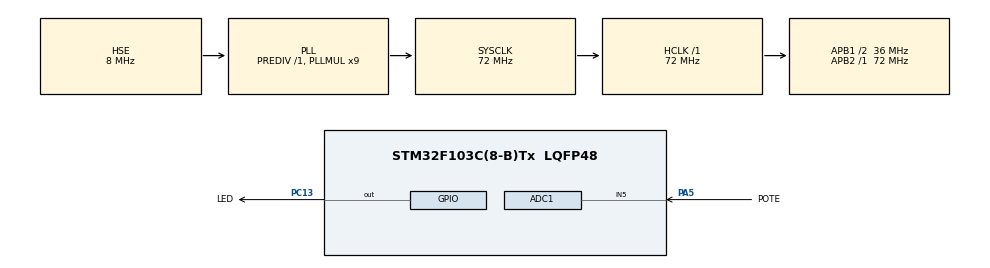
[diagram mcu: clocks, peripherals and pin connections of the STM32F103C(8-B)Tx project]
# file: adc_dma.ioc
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Mcu.Family=STM32F1
RCC.PLLSourceVirtual=RCC_PLLSOURCE_HSE
Dma.ADC1.0.Instance=DMA1_Channel1
ADC1.Rank-0\#ChannelRegularConversion=1
PD1-OSC_OUT.Mode=HSE-External-Oscillator
ADC1.ContinuousConvMode=ENABLE
PC13-TAMPER-RTC.Signal=GPIO_Output
NVIC.TIM1_UP_IRQn=true\:0\:0\:false\:false\:true\:false\:true
PD0-OSC_IN.Signal=RCC_OSC_IN
RCC.APB1CLKDivider=RCC_HCLK_DIV2
RCC.SYSCLKSource=RCC_SYSCLKSOURCE_PLLCLK
ProjectManager.StackSize=0x400
PD1-OSC_OUT.Signal=RCC_OSC_OUT
RCC.ADCPresc=RCC_ADCPCLK2_DIV6
PA13.Signal=SYS_JTMS-SWDIO
Dma.ADC1.0.PeriphDataAlignment=DMA_PDATAALIGN_HALFWORD
ProjectManager.TargetToolchain=STM32CubeIDE
Dma.ADC1.0.Mode=DMA_CIRCULAR
RCC.HCLKFreq_Value=72000000
Dma.ADC1.0.Priority=DMA_PRIORITY_LOW
RCC.APB2TimFreq_Value=72000000
Dma.ADC1.0.Direction=DMA_PERIPH_TO_MEMORY
RCC.USBFreq_Value=72000000
Dma.ADC1.0.MemDataAlignment=DMA_MDATAALIGN_WORD
RCC.AHBFreq_Value=72000000
PD0-OSC_IN.Mode=HSE-External-Oscillator
PA5.Signal=ADCx_IN5
ADC1.Channel-0\#ChannelRegularConversion=ADC_CHANNEL_5
board=custom
PC13-TAMPER-RTC.GPIO_Label=LED
RCC.PLLMUL=RCC_PLL_MUL9
RCC.APB2Freq_Value=72000000
PA14.Mode=Serial_Wire
VP_SYS_VS_tim1.Mode=TIM1
Dma.ADC1.0.PeriphInc=DMA_PINC_DISABLE
PA13.Mode=Serial_Wire
Mcu.Name=STM32F103C(8-B)Tx
ADC1.SamplingTime-0\#ChannelRegularConversion=ADC_SAMPLETIME_1CYCLE_5
RCC.SYSCLKFreq_VALUE=72000000
Mcu.Package=LQFP48
ADC1.master=1
NVIC.TimeBase=TIM1_UP_IRQn
PA5.GPIO_Label=POTE
NVIC.TimeBaseIP=TIM1
PA14.Signal=SYS_JTCK-SWCLK
Dma.ADC1.0.MemInc=DMA_MINC_ENABLE
ProjectManager.HeapSize=0x200
SH.ADCx_IN5.0=ADC1_IN5,IN5
NVIC.PriorityGroup=NVIC_PRIORITYGROUP_4
ADC1.NbrOfConversionFlag=1
RCC.APB1TimFreq_Value=72000000
NVIC.DMA1_Channel1_IRQn=true\:5\:0\:true\:false\:true\:true\:true
Dma.Request0=ADC1
RCC.APB1Freq_Value=36000000

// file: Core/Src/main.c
/* USER CODE BEGIN Header */
/*
 * The following code consists of the following:
 *  - The ADC is set to transfer conversions via DMA to a memory buffer. When the transfer is completed a semaphore will be released.
 *  - A task that is waiting for the semaphore will then read all the values saved in memory, calculate the average,
 *    and finally will turn on/off the led according to a threshold value.
 */
/* USER CODE END Header */
#include "main.h"

/* USER CODE BEGIN Includes */
#include "FreeRTOS.h"
#include "task.h"
#include "semphr.h"
/* USER CODE END Includes */

ADC_HandleTypeDef hadc1;
DMA_HandleTypeDef hdma_adc1;

void SystemClock_Config(void);
static void MX_GPIO_Init(void);
static void MX_DMA_Init(void);
static void MX_ADC1_Init(void);

/* USER CODE BEGIN 0 */

SemaphoreHandle_t transfer_completed;

#define ADC_ARRAY_LENGTH 10
#define THRESHOLD_VALUE 2048

uint32_t adc_data[ADC_ARRAY_LENGTH];

static void Led(void *pvParameters){

	uint32_t average, sum;

	while (1){

		xSemaphoreTake(transfer_completed, portMAX_DELAY);

		sum = 0;
		average = 0;

		for (uint32_t i=0; i<ADC_ARRAY_LENGTH; i++){
			sum += adc_data[i];
		}

		average = sum / ADC_ARRAY_LENGTH;

		if ( average > THRESHOLD_VALUE ) {

			// If the value coming from the queue is greater than the threshold, turn on the led
			HAL_GPIO_WritePin(LED_GPIO_Port, LED_Pin, GPIO_PIN_RESET);

		}
		else {

			// Else turn it off
			HAL_GPIO_WritePin(LED_GPIO_Port, LED_Pin, GPIO_PIN_SET);

		}

	}
}

// Called when the buffer was filled
void HAL_ADC_ConvCpltCallback(ADC_HandleTypeDef* hadc){

	static portBASE_TYPE xHigherPriorityTaskWoken = pdFALSE;

	// Release the semaphore, indicating that the DMA transfer was completed
	xSemaphoreGiveFromISR(transfer_completed, xHigherPriorityTaskWoken);

	portEND_SWITCHING_ISR(xHigherPriorityTaskWoken);
}

/* USER CODE END 0 */

int main(void)
{

  /* MCU Configuration--------------------------------------------------------*/

  /* Reset of all peripherals, Initializes the Flash interface and the Systick. */
  HAL_Init();

  /* Configure the system clock */
  SystemClock_Config();

  /* Initialize all configured peripherals */
  MX_GPIO_Init();
  MX_DMA_Init();
  MX_ADC1_Init();
  /* USER CODE BEGIN 2 */

  vSemaphoreCreateBinary(transfer_completed);

  xTaskCreate(Led, "Led task", configMINIMAL_STACK_SIZE, NULL, 1, NULL);

  // Starts ADC with DMA
  HAL_ADC_Start_DMA(&hadc1, adc_data, ADC_ARRAY_LENGTH);

  vTaskStartScheduler();

  /* USER CODE END 2 */

  /* Infinite loop */

}

void SystemClock_Config(void)
{
  RCC_OscInitTypeDef RCC_OscInitStruct = {0};
  RCC_ClkInitTypeDef RCC_ClkInitStruct = {0};
  RCC_PeriphCLKInitTypeDef PeriphClkInit = {0};

  /** Initializes the RCC Oscillators according to the specified parameters
  * in the RCC_OscInitTypeDef structure.
  */
  RCC_OscInitStruct.OscillatorType = RCC_OSCILLATORTYPE_HSE;
  RCC_OscInitStruct.HSEState = RCC_HSE_ON;
  RCC_OscInitStruct.HSEPredivValue = RCC_HSE_PREDIV_DIV1;
  RCC_OscInitStruct.HSIState = RCC_HSI_ON;
  RCC_OscInitStruct.PLL.PLLState = RCC_PLL_ON;
  RCC_OscInitStruct.PLL.PLLSource = RCC_PLLSOURCE_HSE;
  RCC_OscInitStruct.PLL.PLLMUL = RCC_PLL_MUL9;
  if (HAL_RCC_OscConfig(&RCC_OscInitStruct) != HAL_OK)
  {
    Error_Handler();
  }
  /** Initializes the CPU, AHB and APB buses clocks
  */
  RCC_ClkInitStruct.ClockType = RCC_CLOCKTYPE_HCLK|RCC_CLOCKTYPE_SYSCLK
                              |RCC_CLOCKTYPE_PCLK1|RCC_CLOCKTYPE_PCLK2;
  RCC_ClkInitStruct.SYSCLKSource = RCC_SYSCLKSOURCE_PLLCLK;
  RCC_ClkInitStruct.AHBCLKDivider = RCC_SYSCLK_DIV1;
  RCC_ClkInitStruct.APB1CLKDivider = RCC_HCLK_DIV2;
  RCC_ClkInitStruct.APB2CLKDivider = RCC_HCLK_DIV1;

  if (HAL_RCC_ClockConfig(&RCC_ClkInitStruct, FLASH_LATENCY_2) != HAL_OK)
  {
    Error_Handler();
  }
  PeriphClkInit.PeriphClockSelection = RCC_PERIPHCLK_ADC;
  PeriphClkInit.AdcClockSelection = RCC_ADCPCLK2_DIV6;
  if (HAL_RCCEx_PeriphCLKConfig(&PeriphClkInit) != HAL_OK)
  {
    Error_Handler();
  }
}

static void MX_ADC1_Init(void)
{

  ADC_ChannelConfTypeDef sConfig = {0};

  /** Common config
  */
  hadc1.Instance = ADC1;
  hadc1.Init.ScanConvMode = ADC_SCAN_DISABLE;
  hadc1.Init.ContinuousConvMode = ENABLE;
  hadc1.Init.DiscontinuousConvMode = DISABLE;
  hadc1.Init.ExternalTrigConv = ADC_SOFTWARE_START;
  hadc1.Init.DataAlign = ADC_DATAALIGN_RIGHT;
  hadc1.Init.NbrOfConversion = 1;
  if (HAL_ADC_Init(&hadc1) != HAL_OK)
  {
    Error_Handler();
  }
  /** Configure Regular Channel
  */
  sConfig.Channel = ADC_CHANNEL_5;
  sConfig.Rank = ADC_REGULAR_RANK_1;
  sConfig.SamplingTime = ADC_SAMPLETIME_1CYCLE_5;
  if (HAL_ADC_ConfigChannel(&hadc1, &sConfig) != HAL_OK)
  {
    Error_Handler();
  }

}

static void MX_DMA_Init(void)
{

  /* DMA controller clock enable */
  __HAL_RCC_DMA1_CLK_ENABLE();

  /* DMA interrupt init */
  /* DMA1_Channel1_IRQn interrupt configuration */
  HAL_NVIC_SetPriority(DMA1_Channel1_IRQn, 5, 0);
  HAL_NVIC_EnableIRQ(DMA1_Channel1_IRQn);

}

static void MX_GPIO_Init(void)
{
  GPIO_InitTypeDef GPIO_InitStruct = {0};

  /* GPIO Ports Clock Enable */
  __HAL_RCC_GPIOC_CLK_ENABLE();
  __HAL_RCC_GPIOD_CLK_ENABLE();
  __HAL_RCC_GPIOA_CLK_ENABLE();

  /*Configure GPIO pin Output Level */
  HAL_GPIO_WritePin(LED_GPIO_Port, LED_Pin, GPIO_PIN_RESET);

  /*Configure GPIO pin : LED_Pin */
  GPIO_InitStruct.Pin = LED_Pin;
  GPIO_InitStruct.Mode = GPIO_MODE_OUTPUT_PP;
  GPIO_InitStruct.Pull = GPIO_NOPULL;
  GPIO_InitStruct.Speed = GPIO_SPEED_FREQ_LOW;
  HAL_GPIO_Init(LED_GPIO_Port, &GPIO_InitStruct);

}

 /**
  * @brief  Period elapsed callback in non blocking mode
  * @note   This function is called  when TIM1 interrupt took place, inside
  * HAL_TIM_IRQHandler(). It makes a direct call to HAL_IncTick() to increment
  * a global variable "uwTick" used as application time base.
  * @param  htim : TIM handle
  * @retval None
  */
void HAL_TIM_PeriodElapsedCallback(TIM_HandleTypeDef *htim)
{
  if (htim->Instance == TIM1) {
    HAL_IncTick();
  }
}

void Error_Handler(void)
{
  __disable_irq();
  while (1)
  {
  }
}

/************************ (C) COPYRIGHT STMicroelectronics *****END OF FILE****/
